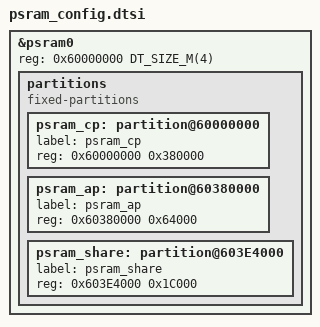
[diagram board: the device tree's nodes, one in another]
#include <listenai/ls_csk6.dtsi>

&psram0 {
    reg = <0x60000000 DT_SIZE_M(4)>;

    partitions {
        compatible = "fixed-partitions";
        #address-cells = <1>;
        #size-cells = <1>;

        psram_cp: partition@60000000 {
            label = "psram_cp";
            reg = <0x60000000 0x380000>;
        };

        psram_ap: partition@60380000 {
            label = "psram_ap";
            reg = <0x60380000 0x64000>;
        };

        psram_share: partition@603E4000  {
            label = "psram_share";
            reg = <0x603E4000 0x1C000>;
        };
    };
};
